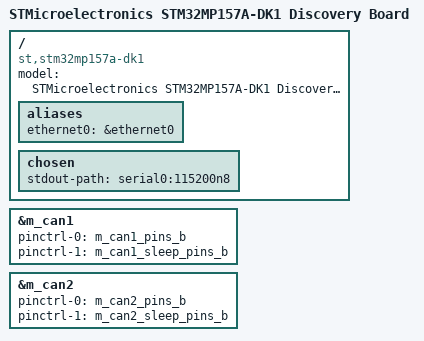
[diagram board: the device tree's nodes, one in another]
// SPDX-License-Identifier: (GPL-2.0+ OR BSD-3-Clause)
/*
 * Copyright (C) STMicroelectronics 2019 - All Rights Reserved
 * Author: Alexandre Torgue <alexandre.torgue@st.com> for STMicroelectronics.
 */

/dts-v1/;

#include "stm32mp157.dtsi"
#include "stm32mp15-pinctrl.dtsi"
#include "stm32mp15xxac-pinctrl.dtsi"
#include "stm32mp15xx-dkx.dtsi"

/ {
	model = "STMicroelectronics STM32MP157A-DK1 Discovery Board";
	compatible = "st,stm32mp157a-dk1", "st,stm32mp157";

	aliases {
		ethernet0 = &ethernet0;
	};

	chosen {
		stdout-path = "serial0:115200n8";
	};
};

/*
 * FDCAN1/FDCAN2 routed to the CN2 (Raspberry Pi compatible) GPIO connector.
 * External CAN FD transceivers (e.g. MCP2562FD) have to be attached:
 *
 * FDCAN1: PA12 (TX) -> CN2 pin 03, PA11 (RX) -> CN2 pin 05 (shared with I2C5)
 * FDCAN2: PB13 (TX) -> CN2 pin 36, PB12 (RX) -> CN2 pin 10 (shared with USART3)
 *
 * I2C5 and USART3 are disabled in stm32mp15xx-dkx.dtsi, so there is no conflict.
 */
&m_can1 {
	pinctrl-names = "default", "sleep";
	pinctrl-0 = <&m_can1_pins_b>;
	pinctrl-1 = <&m_can1_sleep_pins_b>;
	status = "okay";
};

&m_can2 {
	pinctrl-names = "default", "sleep";
	pinctrl-0 = <&m_can2_pins_b>;
	pinctrl-1 = <&m_can2_sleep_pins_b>;
	status = "okay";
};
